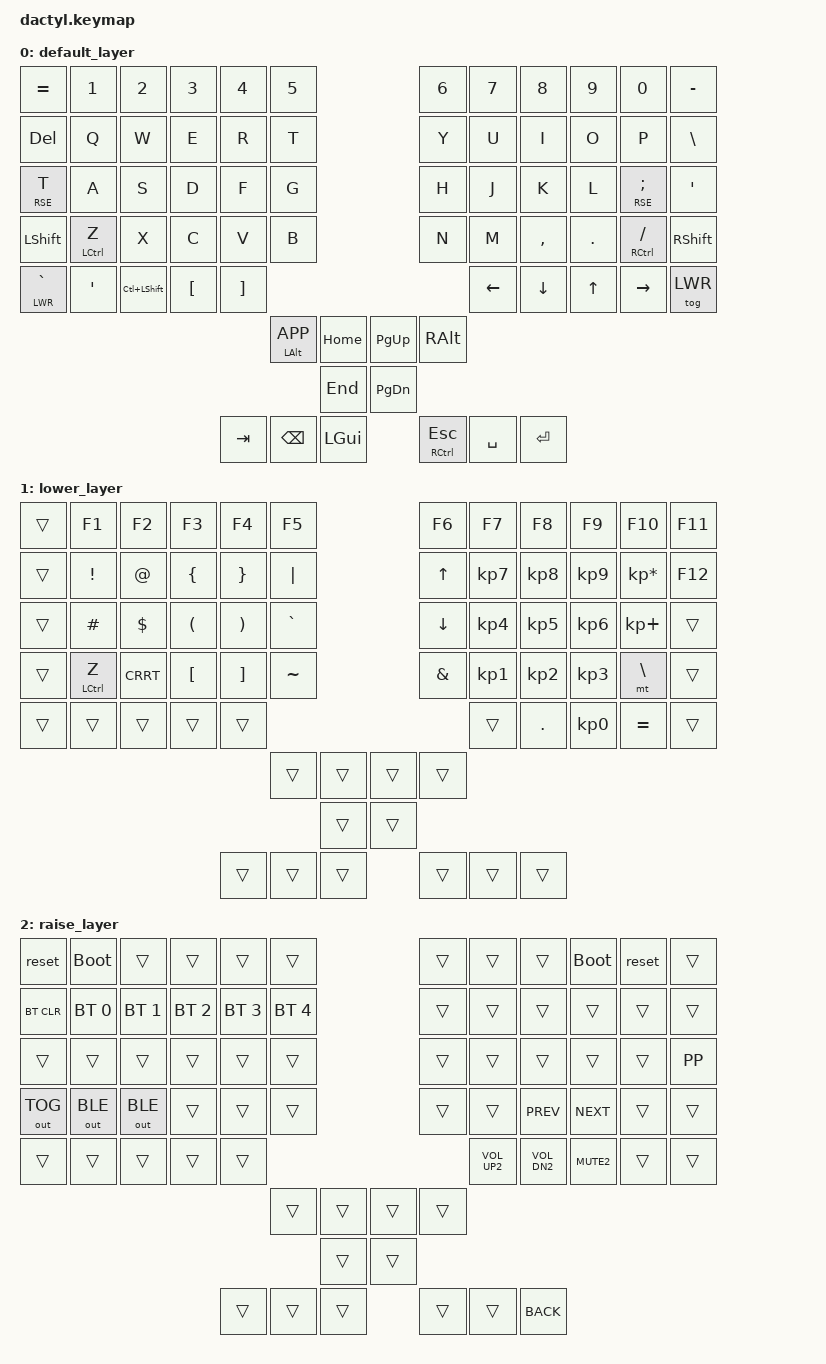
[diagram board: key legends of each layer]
/*
 * Copyright (c) 2020 The ZMK Contributors
 *
 * SPDX-License-Identifier: MIT
 */

#include <behaviors.dtsi>
#include <dt-bindings/zmk/keys.h>
#include <dt-bindings/zmk/bt.h>
#include <dt-bindings/zmk/outputs.h>

#define DEF 0
#define LWR 1
#define RSE 2
#define ADJ 3

/ {
        keymap {
                compatible = "zmk,keymap";

                default_layer {
/* Keymap 0: Basic layer
 *
 * ,-----------------------------------------.                                                                      ,-----------------------------------------.
 * |   =  |   1  |   2  |   3  |   4  |   5  |                                                                      |   6  |   7  |   8  |   9  |   0  |  -   |
 * |------+------+------+------+------+------|                                                                      |------+------+------+------+------+------|
 * | Del  |   Q  |   W  |   E  |   R  |   T  |                                                                      |   Y  |   U  |   I  |   O  |   P  |  \   |
 * |------+------+------+------+------+------|                                                                      |------+------+------+------+------+------|
 * |t/L2|   A  |   S  |   D  |   F  |   G  |                                                                      |   H  |   J  |   K  |   L  |; / L2|'/Cmd |
 * |------+------+------+------+------+------|                                                                      |------+------+------+------+------+------|
 * |LShift|Z/Ctrl|   X  |   C  |   V  |   B  |                                                                      |   N  |   M  |   ,  |   .  |//Ctrl|RShift|
 * |------+------+------+------+------+------'                                                                      `------+------+------+------+------+------|
 * |Grv/L1|  '"  |AltShf|  [   |  ]   |                                                                                    | LEFT | DOWN | UP   | RIGHT| ~L1  |
 * `----------------------------------'                                                                                    `----------------------------------'
 *                                      ,-------------.                                                    ,-------------.
 *                                      | A/App| Home |                                                    | PgUp | Alt  |
 *                               ,------|------|------|                                                    |------+------+------.
 *                               |      |      | End  |                                                    | PgDn |      |      |
 *                               | TAB  |Backsp|------|                                                    |------| Space|Enter |
 *                               |      |ace   | LGUI |                                                    | ^/Esc|      |      |
 *                               `--------------------'                                                    `--------------------'
 */
                        bindings = <
  &kp EQUAL     &kp N1      &kp N2        &kp N3   &kp N4    &kp N5                                    &kp N6 &kp N7   &kp N8    &kp N9  &kp N0         &kp MINUS
  &kp DEL       &kp Q       &kp W         &kp E    &kp R     &kp T                                     &kp Y  &kp U    &kp I     &kp O   &kp P          &kp BSLH
  &lt RSE T   &kp A       &kp S         &kp D    &kp F     &kp G                                     &kp H  &kp J    &kp K     &kp L   &lt RSE SEMI   &kp SQT
  &kp LSHFT     &mt LCTRL Z &kp X         &kp C    &kp V     &kp B                                     &kp N  &kp M    &kp COMMA &kp DOT &mt RCTRL FSLH &kp RSHFT
  &lt LWR GRAVE &kp SQT     &kp LC(LSHFT) &kp LBKT &kp RBKT                                                   &kp LEFT &kp DOWN  &kp UP  &kp RIGHT      &tog LWR
                                                             &mt LALT K_APP &kp HOME         &kp PG_UP &kp RALT
                                                                            &kp END          &kp PG_DN                                   
                                                   &kp TAB   &kp BSPC       &kp LGUI         &mt RCTRL ESC &kp SPACE &kp ENTER   
                        >;
                };
                lower_layer {
/* Keymap 1: Symbol Layer
 *
 * ,-----------------------------------------.                    ,-----------------------------------------.
 * |Versn |  F1  |  F2  |  F3  |  F4  |  F5  |                    |  F6  |  F7  |  F8  |  F9  |  F10 |  F11 |
 * |------+------+------+------+------+------|                    |------+------+------+------+------+------|
 * |      |   !  |   @  |   {  |   }  |   |  |                    |  Up  |   7  |   8  |   9  |   *  |  F12 |
 * |------+------+------+------+------+------|                    |------+------+------+------+------+------|
 * |      |   #  |   $  |   (  |   )  |   `  |                    | Down |   4  |   5  |   6  |   +  |      |
 * |------+------+------+------+------+------|                    |------+------+------+------+------+------|
 * |      |   %  |   ^  |   [  |   ]  |   ~  |                    |   &  |   1  |   2  |   3  |   \  |      |
 * |------+------+------+------+------+------'                    `------+------+------+------+------+------|
 * |      |      |      |      |      |                                  |      |   .  |   0  |   =  |      |
 * `----------------------------------'                                  `----------------------------------'
 *                                      ,-------------.  ,-------------.
 *                                      |      |      |  |      |      |
 *                               ,------|------|------|  |------+------+------.
 *                               |      |      |      |  |      |      |      |
 *                               |      |      |------|  |------|      |      |
 *                               |      |      |      |  |      |      |      |
 *                               `--------------------'  `--------------------'
 */
                        bindings = <
  &trans &kp F1      &kp F2   &kp F3   &kp F4    &kp F5        &kp F6   &kp F7    &kp F8    &kp F9    &kp F10         &kp F11
  &trans &kp EXCL    &kp AT   &kp LBRC &kp RBRC  &kp PIPE      &kp UP   &kp KP_N7 &kp KP_N8 &kp KP_N9 &kp KP_MULTIPLY &kp F12
  &trans &kp HASH    &kp DLLR &kp LPAR &kp RPAR  &kp GRAVE     &kp DOWN &kp KP_N4 &kp KP_N5 &kp KP_N6 &kp KP_PLUS     &trans
  &trans &mt LCTRL Z &kp CRRT &kp LBKT &kp RBKT  &kp TILDE     &kp AMPS &kp KP_N1 &kp KP_N2 &kp KP_N3 &mt BSLH        &trans
  &trans &trans      &trans   &trans   &trans                           &trans    &kp DOT   &kp KP_N0 &kp EQUAL       &trans
                                          &trans    &trans        &trans   &trans                      
                                                    &trans        &trans                                  
                                 &trans   &trans    &trans        &trans   &trans    &trans  
  
                        >;
                };

                raise_layer {
/* Keymap 2: Media and mouse keys
 * ,-----------------------------------------.                    ,-----------------------------------------.
 * |Reset |BOTLDR|      |      |      |      |                    |      |      |      |BOTLDR|RESET |      |
 * |------+------+------+------+------+------|                    |------+------+------+------+------+------|
 * |BT_CLR|BT_0  |BT_1  |BT_2  |BT_3  |BT_4  |                    |      |      |      |      |      |      |
 * |------+------+------+------+------+------|                    |------+------+------+------+------+------|
 * |      |      |      |      |      |      |                    |      |      |      |      |      | Play |
 * |------+------+------+------+------+------|                    |------+------+------+------+------+------|
 * |OUT_TG|OUT_BL|OUT_US|      |      |      |                    |      |      | Prev | Next |      |      |
 * |------+------+------+------+------+------'                    `------+------+------+------+------+------|
 * |      |      |      |      |      |                                  | VolUp| VolDn| Mute |      |      |
 * `----------------------------------'                                  `----------------------------------'
 *                                      ,-------------.  ,-------------.
 *                                      |      |      |  |      |      |
 *                               ,------|------|------|  |------+------+------.
 *                               |      |      |      |  |      |      |Brwser|
 *                               |      |      |------|  |------|      |Back  |
 *                               |      |      |      |  |      |      |      |
 *                               `--------------------'  `--------------------'
 *
 */
                        bindings = <
          &reset       &bootloader  &trans       &trans       &trans       &trans          &trans &trans        &trans        &bootloader &reset &trans
          &bt BT_CLR   &bt BT_SEL 0 &bt BT_SEL 1 &bt BT_SEL 2 &bt BT_SEL 3 &bt BT_SEL 4    &trans &trans        &trans        &trans      &trans &trans
          &trans       &trans       &trans       &trans       &trans       &trans          &trans &trans        &trans        &trans      &trans &kp K_PP
          &out OUT_TOG &out OUT_BLE &out OUT_BLE &trans       &trans       &trans          &trans &trans        &kp K_PREV    &kp K_NEXT  &trans &trans
          &trans       &trans       &trans       &trans       &trans                              &kp K_VOL_UP2 &kp K_VOL_DN2 &kp K_MUTE2 &trans &trans
                                                              &trans       &trans          &trans &trans                      
                                                                           &trans          &trans                                  
                                                 &trans       &trans       &trans          &trans &trans        &kp K_BACK 
       
                             >;
                };
        };
};
